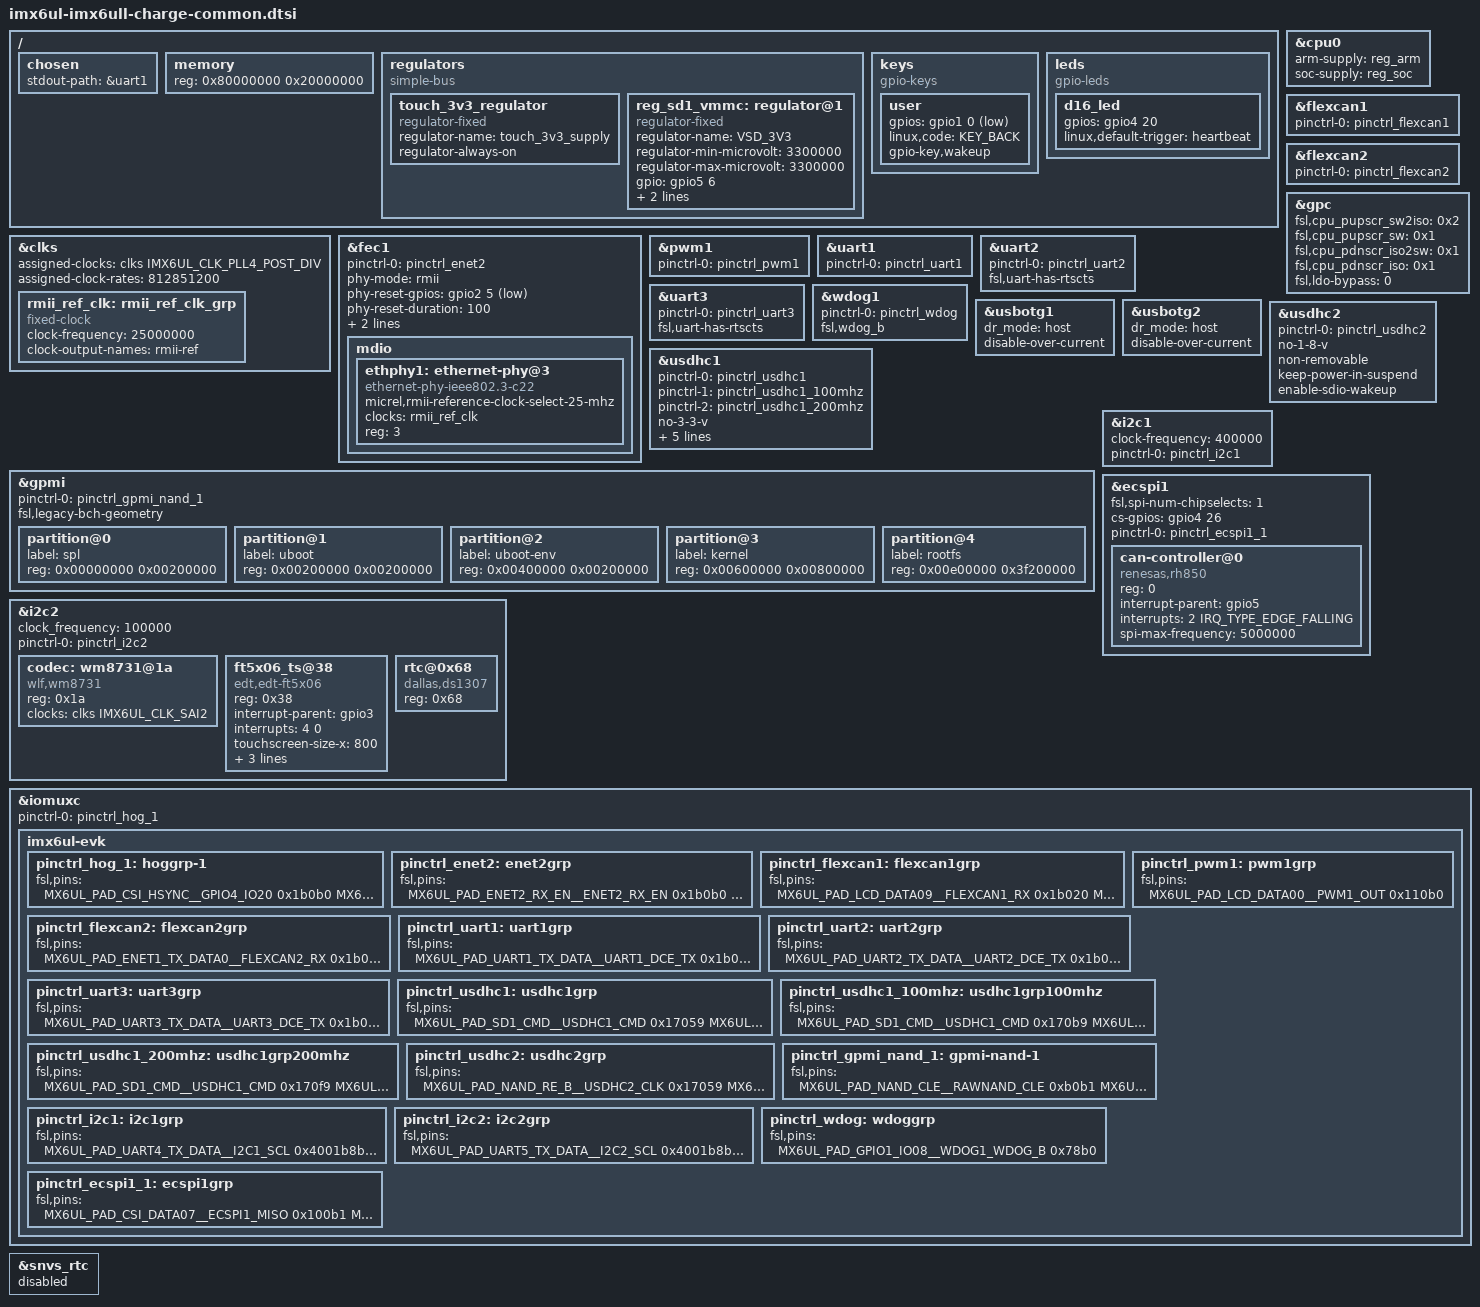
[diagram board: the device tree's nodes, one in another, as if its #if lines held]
/*
 * Copyright (C) 2015 Freescale Semiconductor, Inc.
 *
 * Copyright (C) 2017 charge Ltd. - http://www.charge.auto
 *
 * This program is free software; you can redistribute it and/or modify
 * it under the terms of the GNU General Public License version 2 as
 * published by the Free Software Foundation.
 */
/* #define WIFI */
/* #define EMMC */
/* #define  NAND  */

/*#define  CHARGE*/
#define  CHARGE
/ {
	chosen {
		stdout-path = &uart1;
	};

	memory {
		reg = <0x80000000 0x20000000>;
	};

/*	backlight {
		status = "disabled";
	};

	pxp_v4l2 {
		 status = "disabled";
	};
*/
	regulators {
		compatible = "simple-bus";
		#address-cells = <1>;
		#size-cells = <0>;

		touch_3v3_regulator: touch_3v3_regulator {
			compatible = "regulator-fixed";
			regulator-name = "touch_3v3_supply";
			regulator-always-on;
			status = "okay";
		};

#ifdef WIFI
#ifdef CHARGE
/* force VMMC1 to always on so BT can operate independently of Wi-Fi */
		reg_sd1_vmmc: regulator@1 {
			compatible = "regulator-fixed";
			regulator-name = "VSD_3V3";
			regulator-min-microvolt = <3300000>;
			regulator-max-microvolt = <3300000>;
			gpio = <&gpio2 7 GPIO_ACTIVE_HIGH>;	/* WL_REG_ON */
			enable-active-high;
			regulator-always-on;
		};
#endif
#ifdef VAR
		reg_sd1_vmmc: regulator@1 {
			compatible = "regulator-fixed";
			regulator-name = "VSD_3V3";
			regulator-min-microvolt = <3300000>;
			regulator-max-microvolt = <3300000>;
			gpio = <&gpio5 6 GPIO_ACTIVE_HIGH>;	/* WL_REG_ON: SNVS_TAMPER1 (gpio5_6) */
			enable-active-high;
			regulator-always-on;
		};
#endif
#endif
		
	};

	/*sound {  status = "disabled";
	};*/

	keys {
		compatible = "gpio-keys";

		user {
			gpios = <&gpio1 0 GPIO_ACTIVE_LOW>;
			linux,code = <KEY_BACK>;
			gpio-key,wakeup;
		};
	};

	leds {
		compatible = "gpio-leds";

		d16_led {
			gpios = <&gpio4 20 0>;
			linux,default-trigger = "heartbeat";
		};
	};
};

&cpu0 {
	arm-supply = <&reg_arm>;
	soc-supply = <&reg_soc>;
};

&clks {
	/* ref_clk for micrel ethernet phy */
	rmii_ref_clk: rmii_ref_clk_grp {
		compatible = "fixed-clock";
		#clock-cells = <0>;
		clock-frequency = <25000000>;
		clock-output-names = "rmii-ref";
	};
};

&clks {
	assigned-clocks = <&clks IMX6UL_CLK_PLL4_POST_DIV>;
	assigned-clock-rates = <812851200>;
};
#ifdef CHARGE
&fec1 {
	pinctrl-names = "default";
	pinctrl-0 = <&pinctrl_enet2>;
	phy-mode = "rmii";
	phy-reset-gpios=<&gpio2 5 1>;
	phy-reset-duration=<100>;
	phy-reset-on-resume;
	phy-handle = <&ethphy1>;
	status = "okay";
	mdio {
		#address-cells = <1>;
		#size-cells = <0>;

		ethphy1: ethernet-phy@3 {
			compatible = "ethernet-phy-ieee802.3-c22";
			micrel,rmii-reference-clock-select-25-mhz;
			clocks = <&rmii_ref_clk>;
			clock-names = "rmii-ref";
			reg = <3>;
		};
	};
};
#endif
#ifdef VAR
&fec1 {
	pinctrl-names = "default";
	pinctrl-0 = <&pinctrl_enet2>;
	phy-mode = "rmii";
	phy-handle = <&ethphy1>;
	phy-reset-gpios=<&gpio2 5 1>;
	phy-reset-duration=<100>;
	phy-reset-on-resume;
	status = "okay";
	mdio {
		#address-cells = <1>;
		#size-cells = <0>;

		ethphy1: ethernet-phy@3 {
			compatible = "ethernet-phy-ieee802.3-c22";
			micrel,rmii-reference-clock-select-25-mhz;
			clocks = <&rmii_ref_clk>;
			clock-names = "rmii-ref";
			reg = <3>;
		};
	};
};
#endif
&flexcan1 {
	pinctrl-names = "default";
	pinctrl-0 = <&pinctrl_flexcan1>;
	status = "okay";
};
#ifdef CHARGE
&flexcan2 {
	pinctrl-names = "default";
	pinctrl-0 = <&pinctrl_flexcan2>;
	status = "okay";
};
#endif
&gpc {
	fsl,cpu_pupscr_sw2iso = <0x2>;
	fsl,cpu_pupscr_sw = <0x1>;
	fsl,cpu_pdnscr_iso2sw = <0x1>;
	fsl,cpu_pdnscr_iso = <0x1>;
	fsl,ldo-bypass = <0>; /* DCDC, ldo-enable */
};
/*
&lcdif {
 status = "disabled";
};
*/
&pwm1 {
	pinctrl-names = "default";
	pinctrl-0 = <&pinctrl_pwm1>;
	status = "okay";
};
/*
&pxp {
	
 status = "disabled";
};

&sai2 {
 status = "disabled";
};

&adc1 {
	
 status = "disabled";
};

&tsc {
 status = "disabled";
};
*/
/* Console UART */
&uart1 {
	pinctrl-names = "default";
	pinctrl-0 = <&pinctrl_uart1>;
	status = "okay";
};

/* Bluetooth UART */
&uart2 {
	pinctrl-names = "default";
	pinctrl-0 = <&pinctrl_uart2>;
	fsl,uart-has-rtscts;
	status = "okay";
};

/* ttymxc2 UART */
&uart3 {
	pinctrl-names = "default";
	pinctrl-0 = <&pinctrl_uart3>;
	fsl,uart-has-rtscts;
	status = "okay";
};

&wdog1 {
	pinctrl-names = "default";
	pinctrl-0 = <&pinctrl_wdog>;
	fsl,wdog_b;
};

&usbotg1 {
	dr_mode = "host";
	disable-over-current;
	status = "okay";
};

&usbotg2 {
	dr_mode = "host";
	disable-over-current;
	status = "okay";
};

#ifdef WIFI
/*  Wi-Fi/BT SD Card Slot Definition */
&usdhc1 {
	pinctrl-names = "default", "state_100mhz", "state_200mhz";
	pinctrl-0 = <&pinctrl_usdhc1>;
	pinctrl-1 = <&pinctrl_usdhc1_100mhz>;
	pinctrl-2 = <&pinctrl_usdhc1_200mhz>;
	no-3-3-v;
	keep-power-in-suspend;
	enable-sdio-wakeup;
	vmmc-supply = <&reg_sd1_vmmc>;
	wifi-host;			/* add hook for SD card detect mechanism */
	non-removable;
	status = "okay";
};
#else
&usdhc1 {
	pinctrl-names = "default", "state_100mhz", "state_200mhz";
	pinctrl-0 = <&pinctrl_usdhc1>;
	pinctrl-1 = <&pinctrl_usdhc1_100mhz>;
	pinctrl-2 = <&pinctrl_usdhc1_200mhz>;
	no-3-3-v;
	keep-power-in-suspend;
	enable-sdio-wakeup;
/*	cd-gpios = <&gpio4 19 GPIO_ACTIVE_LOW>;
	non-removable;*/
	cd-gpios = <&gpio5 1 GPIO_ACTIVE_LOW>;
	status = "okay";
};
#endif

#ifdef NAND
&gpmi {
	pinctrl-names = "default";
	pinctrl-0 = <&pinctrl_gpmi_nand_1>;
	fsl,legacy-bch-geometry;
	status = "okay";

	partition@0 {
		label = "spl";
		reg = <0x00000000 0x00200000>;
	};

	partition@1 {
		label = "uboot";
		reg = <0x00200000 0x00200000>;
	};

	partition@2 {
		label = "uboot-env";
		reg = <0x00400000 0x00200000>;
	};

	partition@3 {
		label = "kernel";
		reg = <0x00600000 0x00800000>;
	};

	partition@4 {
		label = "rootfs";
		reg = <0x00e00000 0x3f200000>;
	};
};

&usdhc2 {
	status = "disabled";
};
#endif

#ifdef EMMC
&usdhc2 {
	pinctrl-names = "default";
	pinctrl-0 = <&pinctrl_usdhc2>;
	no-1-8-v;
	non-removable;
	keep-power-in-suspend;
	enable-sdio-wakeup;
	status = "okay";
};
#endif

&i2c1 {
	clock-frequency = <400000>;
	pinctrl-names = "default";
	pinctrl-0 = <&pinctrl_i2c1>;
	status = "okay";
};

&i2c2 {
	clock_frequency = <100000>;
	pinctrl-names = "default";
	pinctrl-0 = <&pinctrl_i2c2>;
	status = "okay";

	codec: wm8731@1a {
		compatible = "wlf,wm8731";
		reg = <0x1a>;
		clocks = <&clks IMX6UL_CLK_SAI2>;
		clock-names = "mclk";
	};

	ft5x06_ts@38 {
		compatible = "edt,edt-ft5x06";
		reg = <0x38>;
		interrupt-parent = <&gpio3>;
		interrupts = <4 0>;
		touchscreen-size-x = <800>;
		touchscreen-size-y = <480>;
		touchscreen-inverted-x;
		touchscreen-inverted-y;
	};

	/* DS1307 RTC module */
	rtc@0x68 {
		compatible = "dallas,ds1307";
		reg = <0x68>;
	};
};

&ecspi1 {
	fsl,spi-num-chipselects = <1>;
	cs-gpios = <&gpio4 26 0>;
	pinctrl-names = "default";
	pinctrl-0 = <&pinctrl_ecspi1_1>;
	status = "okay";

	can-controller@0 {
		compatible = "renesas,rh850";
		reg = <0>;
		interrupt-parent = <&gpio5>;
 		interrupts = <2 IRQ_TYPE_EDGE_FALLING>;
		spi-max-frequency = <5000000>;
	};


};

&iomuxc {
	pinctrl-names = "default";
	pinctrl-0 = <&pinctrl_hog_1>;
	imx6ul-evk {
		pinctrl_hog_1: hoggrp-1 {
			fsl,pins = <
				MX6UL_PAD_CSI_HSYNC__GPIO4_IO20		0x1b0b0	/* User LED */
				MX6UL_PAD_GPIO1_IO00__GPIO1_IO00	0x17059	/* User Button */
				MX6UL_PAD_GPIO1_IO07__ENET2_MDC		0x1b0b0
				MX6UL_PAD_GPIO1_IO06__ENET2_MDIO	0x1b0b0
#ifdef WIFI
				MX6UL_PAD_GPIO1_IO03__REF_CLK_32K	0x03029	/* WLAN Slow Clock */
#endif
			>;
		};

#ifdef CHARGE
		pinctrl_enet2: enet2grp {
			fsl,pins = <
				MX6UL_PAD_GPIO1_IO07__ENET2_MDC		0x1b0b0
				MX6UL_PAD_GPIO1_IO06__ENET2_MDIO	0x1b0b0
				MX6UL_PAD_ENET2_RX_EN__ENET2_RX_EN	0x1b0b0
				MX6UL_PAD_ENET2_RX_ER__ENET2_RX_ER	0x1b0b0
				MX6UL_PAD_ENET2_RX_DATA0__ENET2_RDATA00	0x1b0b0
				MX6UL_PAD_ENET2_RX_DATA1__ENET2_RDATA01	0x1b0b0
				MX6UL_PAD_ENET2_TX_EN__ENET2_TX_EN	0x1b0b0
				MX6UL_PAD_ENET2_TX_DATA0__ENET2_TDATA00	0x1b0b0
				MX6UL_PAD_ENET2_TX_DATA1__ENET2_TDATA01	0x1b0b0
				MX6UL_PAD_ENET2_TX_CLK__ENET2_REF_CLK2	0x4001b031
				MX6UL_PAD_ENET1_TX_EN__GPIO2_IO05	0x1b0b0
			>;
		};

		pinctrl_flexcan1: flexcan1grp{
			fsl,pins = <
				MX6UL_PAD_ENET1_RX_DATA1__FLEXCAN1_RX 	0x1b020
				MX6UL_PAD_ENET1_RX_DATA0__FLEXCAN1_TX 	0x1b020
			>;
		};

		pinctrl_flexcan2: flexcan2grp{
			fsl,pins = <
				MX6UL_PAD_ENET1_TX_DATA0__FLEXCAN2_RX	0x1b020
				MX6UL_PAD_ENET1_RX_EN__FLEXCAN2_TX	0x1b020
			>;
		};
#endif
#ifdef VAR
		pinctrl_enet2: enet2grp {
			fsl,pins = <
				MX6UL_PAD_ENET2_RX_EN__ENET2_RX_EN	0x1b0b0
				MX6UL_PAD_ENET2_RX_ER__ENET2_RX_ER	0x1b0b0
				MX6UL_PAD_ENET2_RX_DATA0__ENET2_RDATA00	0x1b0b0
				MX6UL_PAD_ENET2_RX_DATA1__ENET2_RDATA01	0x1b0b0
				MX6UL_PAD_ENET2_TX_EN__ENET2_TX_EN	0x1b0b0
				MX6UL_PAD_ENET2_TX_DATA0__ENET2_TDATA00	0x1b0b0
				MX6UL_PAD_ENET2_TX_DATA1__ENET2_TDATA01	0x1b0b0
				MX6UL_PAD_ENET2_TX_CLK__ENET2_REF_CLK2	0x4001b031
				MX6UL_PAD_JTAG_MOD__GPIO1_IO10		0x1b0b0
			>;
		};
		pinctrl_flexcan1: flexcan1grp{
			fsl,pins = <
				MX6UL_PAD_LCD_DATA09__FLEXCAN1_RX	0x1b020
				MX6UL_PAD_LCD_DATA08__FLEXCAN1_TX	0x1b020
			>;
		};

		/*pinctrl_flexcan2: flexcan2grp{
			fsl,pins = <
				MX6UL_PAD_UART2_RTS_B__FLEXCAN2_RX	0x1b020
				MX6UL_PAD_UART2_CTS_B__FLEXCAN2_TX	0x1b020
			>;
		};*/

#endif
		pinctrl_pwm1: pwm1grp {
			fsl,pins = <
				MX6UL_PAD_LCD_DATA00__PWM1_OUT		0x110b0
			>;
		};

		pinctrl_uart1: uart1grp {
			fsl,pins = <
				MX6UL_PAD_UART1_TX_DATA__UART1_DCE_TX	0x1b0b1
				MX6UL_PAD_UART1_RX_DATA__UART1_DCE_RX	0x1b0b1
			>;
		};

		pinctrl_uart2: uart2grp {
			fsl,pins = <
				MX6UL_PAD_UART2_TX_DATA__UART2_DCE_TX	0x1b0b1
				MX6UL_PAD_UART2_RX_DATA__UART2_DCE_RX	0x1b0b1
				MX6UL_PAD_UART2_CTS_B__UART2_DCE_CTS	0x1b0b1
				MX6UL_PAD_UART2_RTS_B__UART2_DCE_RTS	0x1b0b1
			>;
		};

		pinctrl_uart3: uart3grp {
			fsl,pins = <
				MX6UL_PAD_UART3_TX_DATA__UART3_DCE_TX	0x1b0b1
				MX6UL_PAD_UART3_RX_DATA__UART3_DCE_RX	0x1b0b1
				MX6UL_PAD_UART3_CTS_B__UART3_DCE_CTS	0x1b0b1
				MX6UL_PAD_UART3_RTS_B__UART3_DCE_RTS	0x1b0b1
			>;
		};

		pinctrl_usdhc1: usdhc1grp {
			fsl,pins = <
				MX6UL_PAD_SD1_CMD__USDHC1_CMD		0x17059
				MX6UL_PAD_SD1_CLK__USDHC1_CLK		0x17059
				MX6UL_PAD_SD1_DATA0__USDHC1_DATA0	0x17059
				MX6UL_PAD_SD1_DATA1__USDHC1_DATA1	0x17059
				MX6UL_PAD_SD1_DATA2__USDHC1_DATA2	0x17059
				MX6UL_PAD_SD1_DATA3__USDHC1_DATA3	0x17059
				/*MX6UL_PAD_CSI_VSYNC__GPIO4_IO19		0x1b0b1	*/ 
				MX6UL_PAD_SNVS_TAMPER1__GPIO5_IO01	/*0x1b0b1 SD card detect */
			>;
		};

		pinctrl_usdhc1_100mhz: usdhc1grp100mhz {
			fsl,pins = <
				MX6UL_PAD_SD1_CMD__USDHC1_CMD		0x170b9
				MX6UL_PAD_SD1_CLK__USDHC1_CLK		0x100b9
				MX6UL_PAD_SD1_DATA0__USDHC1_DATA0	0x170b9
				MX6UL_PAD_SD1_DATA1__USDHC1_DATA1	0x170b9
				MX6UL_PAD_SD1_DATA2__USDHC1_DATA2	0x170b9
				MX6UL_PAD_SD1_DATA3__USDHC1_DATA3	0x170b9
				/*MX6UL_PAD_CSI_VSYNC__GPIO4_IO19		0x1b0b1	*/ /*SD card detect */
				MX6UL_PAD_SNVS_TAMPER1__GPIO5_IO01	0x1b0b1
			>;
		};

		pinctrl_usdhc1_200mhz: usdhc1grp200mhz {
			fsl,pins = <
				MX6UL_PAD_SD1_CMD__USDHC1_CMD		0x170f9
				MX6UL_PAD_SD1_CLK__USDHC1_CLK		0x100f9
				MX6UL_PAD_SD1_DATA0__USDHC1_DATA0	0x170f9
				MX6UL_PAD_SD1_DATA1__USDHC1_DATA1	0x170f9
				MX6UL_PAD_SD1_DATA2__USDHC1_DATA2	0x170f9
				MX6UL_PAD_SD1_DATA3__USDHC1_DATA3	0x170f9
				/*MX6UL_PAD_CSI_VSYNC__GPIO4_IO19		0x1b0b1	 *//*SD card detect */
				MX6UL_PAD_SNVS_TAMPER1__GPIO5_IO01	0x1b0b1
			>;
		};
#ifdef EMMC
		pinctrl_usdhc2: usdhc2grp {
			fsl,pins = <
				MX6UL_PAD_NAND_RE_B__USDHC2_CLK		0x17059
				MX6UL_PAD_NAND_WE_B__USDHC2_CMD		0x17059
				MX6UL_PAD_NAND_DATA00__USDHC2_DATA0	0x17059
				MX6UL_PAD_NAND_DATA01__USDHC2_DATA1	0x17059
				MX6UL_PAD_NAND_DATA02__USDHC2_DATA2	0x17059
				MX6UL_PAD_NAND_DATA03__USDHC2_DATA3	0x17059
			>;
		};
#endif
#ifdef NAND
		pinctrl_gpmi_nand_1: gpmi-nand-1 {
			fsl,pins = <
				MX6UL_PAD_NAND_CLE__RAWNAND_CLE		0xb0b1
				MX6UL_PAD_NAND_ALE__RAWNAND_ALE		0xb0b1
				MX6UL_PAD_NAND_WP_B__RAWNAND_WP_B	0xb0b1
				MX6UL_PAD_NAND_READY_B__RAWNAND_READY_B	0xb000
				MX6UL_PAD_NAND_CE0_B__RAWNAND_CE0_B	0xb0b1
				MX6UL_PAD_NAND_CE1_B__RAWNAND_CE1_B	0xb0b1
				MX6UL_PAD_NAND_RE_B__RAWNAND_RE_B	0xb0b1
				MX6UL_PAD_NAND_WE_B__RAWNAND_WE_B	0xb0b1
				MX6UL_PAD_NAND_DATA00__RAWNAND_DATA00	0xb0b1
				MX6UL_PAD_NAND_DATA01__RAWNAND_DATA01	0xb0b1
				MX6UL_PAD_NAND_DATA02__RAWNAND_DATA02	0xb0b1
				MX6UL_PAD_NAND_DATA03__RAWNAND_DATA03	0xb0b1
				MX6UL_PAD_NAND_DATA04__RAWNAND_DATA04	0xb0b1
				MX6UL_PAD_NAND_DATA05__RAWNAND_DATA05	0xb0b1
				MX6UL_PAD_NAND_DATA06__RAWNAND_DATA06	0xb0b1
				MX6UL_PAD_NAND_DATA07__RAWNAND_DATA07	0xb0b1
			>;
		};
#endif

		pinctrl_i2c1: i2c1grp {
			fsl,pins = <
				MX6UL_PAD_UART4_TX_DATA__I2C1_SCL	0x4001b8b0
				MX6UL_PAD_UART4_RX_DATA__I2C1_SDA	0x4001b8b0
			>;
		};

		pinctrl_i2c2: i2c2grp {
			fsl,pins = <
				MX6UL_PAD_UART5_TX_DATA__I2C2_SCL	0x4001b8b0
				MX6UL_PAD_UART5_RX_DATA__I2C2_SDA	0x4001b8b0
			>;
		};

		
		pinctrl_wdog: wdoggrp {
			fsl,pins = <
				MX6UL_PAD_GPIO1_IO08__WDOG1_WDOG_B	0x78b0
			>;
		};
		pinctrl_ecspi1_1: ecspi1grp {
			fsl,pins = <
				MX6UL_PAD_CSI_DATA07__ECSPI1_MISO	0x100b1
				MX6UL_PAD_CSI_DATA06__ECSPI1_MOSI	0x100b1
				MX6UL_PAD_CSI_DATA04__ECSPI1_SCLK	0x100b1
				MX6UL_PAD_CSI_DATA05__GPIO4_IO26	0x80000000
				MX6UL_PAD_SNVS_TAMPER2__GPIO5_IO02      0x1b0b1 
			>;
		};
	};
};

&snvs_rtc {
       status = "disabled";
};

